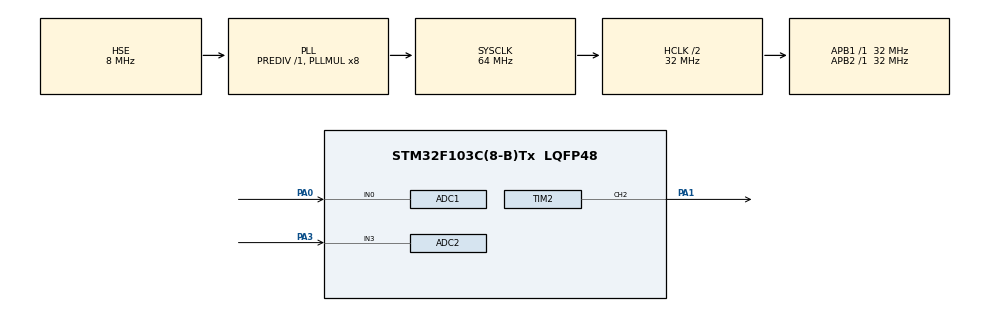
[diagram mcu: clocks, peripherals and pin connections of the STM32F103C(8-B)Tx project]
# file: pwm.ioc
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ADC1.Channel-0\#ChannelRegularConversion=ADC_CHANNEL_0
ADC1.ContinuousConvMode=DISABLE
ADC1.DataAlign=ADC_DATAALIGN_RIGHT
ADC1.DiscontinuousConvMode=DISABLE
ADC1.EnableAnalogWatchDog=false
ADC1.EnableRegularConversion=ENABLE
ADC1.ExternalTrigConvEdgeChoice=NONE
ADC1.InjNumberOfConversion=0
ADC1.NbrOfConversion=1
ADC1.NbrOfConversionFlag=1
ADC1.Rank-0\#ChannelRegularConversion=1
ADC1.SamplingTime-0\#ChannelRegularConversion=ADC_SAMPLETIME_55CYCLES_5
ADC1.ScanConvMode=ADC_SCAN_DISABLE
ADC1.master=1
ADC2.Channel-4\#ChannelRegularConversion=ADC_CHANNEL_3
ADC2.NbrOfConversionFlag=1
ADC2.Rank-4\#ChannelRegularConversion=1
ADC2.SamplingTime-4\#ChannelRegularConversion=ADC_SAMPLETIME_55CYCLES_5
Mcu.Family=STM32F1
Mcu.Name=STM32F103C(8-B)Tx
Mcu.Package=LQFP48
NVIC.ADC1_2_IRQn=true\:0\:0\:false\:false\:true
NVIC.PriorityGroup=NVIC_PRIORITYGROUP_4
PA0-WKUP.Signal=ADCx_IN0
PA1.Signal=S_TIM2_CH2
PA13.Mode=JTAG_5_pin
PA13.Signal=SYS_JTMS-SWDIO
PA14.Mode=JTAG_5_pin
PA14.Signal=SYS_JTCK-SWCLK
PA15.Mode=JTAG_5_pin
PA15.Signal=SYS_JTDI
PA3.Signal=ADCx_IN3
PB3.Mode=JTAG_5_pin
PB3.Signal=SYS_JTDO-TRACESWO
PB4.Mode=JTAG_5_pin
PB4.Signal=SYS_NJTRST
PD0-OSC_IN.Mode=HSE-External-Oscillator
PD0-OSC_IN.Signal=RCC_OSC_IN
PD1-OSC_OUT.Mode=HSE-External-Oscillator
PD1-OSC_OUT.Signal=RCC_OSC_OUT
ProjectManager.HeapSize=0x200
ProjectManager.StackSize=0x400
ProjectManager.TargetToolchain=MDK-ARM V5
RCC.ADCPresc=RCC_ADCPCLK2_DIV4
RCC.AHBCLKDivider=RCC_SYSCLK_DIV2
RCC.AHBFreq_Value=32000000
RCC.APB1Freq_Value=32000000
RCC.APB1TimFreq_Value=32000000
RCC.APB2Freq_Value=32000000
RCC.APB2TimFreq_Value=32000000
RCC.HCLKFreq_Value=32000000
RCC.HSIState=RCC_HSI_ON
RCC.PLLMUL=RCC_PLL_MUL8
RCC.PLLSourceVirtual=RCC_PLLSOURCE_HSE
RCC.SYSCLKFreq_VALUE=64000000
RCC.SYSCLKSource=RCC_SYSCLKSOURCE_PLLCLK
RCC.USBFreq_Value=64000000
SH.ADCx_IN0.0=ADC1_IN0,IN0
SH.ADCx_IN3.0=ADC2_IN3,IN3
SH.S_TIM2_CH2.0=TIM2_CH2,PWM Generation2 CH2
TIM2.Channel-PWM\ Generation2\ CH2=TIM_CHANNEL_2
TIM2.OCFastMode_PWM-PWM\ Generation2\ CH2=TIM_OCFAST_ENABLE
TIM2.Period=20
TIM2.Prescaler=32
TIM2.Pulse-PWM\ Generation2\ CH2=10
board=pwm

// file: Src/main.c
/**
  ******************************************************************************
  * File Name          : main.c
  * Description        : Main program body
  ******************************************************************************
  *
  * COPYRIGHT(c) 2017 STMicroelectronics
  *
  * Redistribution and use in source and binary forms, with or without modification,
  * are permitted provided that the following conditions are met:
  *   1. Redistributions of source code must retain the above copyright notice,
  *      this list of conditions and the following disclaimer.
  *   2. Redistributions in binary form must reproduce the above copyright notice,
  *      this list of conditions and the following disclaimer in the documentation
  *      and/or other materials provided with the distribution.
  *   3. Neither the name of STMicroelectronics nor the names of its contributors
  *      may be used to endorse or promote products derived from this software
  *      without specific prior written permission.
  *
  * THIS SOFTWARE IS PROVIDED BY THE COPYRIGHT HOLDERS AND CONTRIBUTORS "AS IS"
  * AND ANY EXPRESS OR IMPLIED WARRANTIES, INCLUDING, BUT NOT LIMITED TO, THE
  * IMPLIED WARRANTIES OF MERCHANTABILITY AND FITNESS FOR A PARTICULAR PURPOSE ARE
  * DISCLAIMED. IN NO EVENT SHALL THE COPYRIGHT HOLDER OR CONTRIBUTORS BE LIABLE
  * FOR ANY DIRECT, INDIRECT, INCIDENTAL, SPECIAL, EXEMPLARY, OR CONSEQUENTIAL
  * DAMAGES (INCLUDING, BUT NOT LIMITED TO, PROCUREMENT OF SUBSTITUTE GOODS OR
  * SERVICES; LOSS OF USE, DATA, OR PROFITS; OR BUSINESS INTERRUPTION) HOWEVER
  * CAUSED AND ON ANY THEORY OF LIABILITY, WHETHER IN CONTRACT, STRICT LIABILITY,
  * OR TORT (INCLUDING NEGLIGENCE OR OTHERWISE) ARISING IN ANY WAY OUT OF THE USE
  * OF THIS SOFTWARE, EVEN IF ADVISED OF THE POSSIBILITY OF SUCH DAMAGE.
  *
  ******************************************************************************
  */
#include "stm32f1xx_hal.h"

ADC_HandleTypeDef hadc1;
ADC_HandleTypeDef hadc2;

TIM_HandleTypeDef htim2;

/* USER CODE BEGIN PV */
/* Private variables ---------------------------------------------------------*/

volatile uint16_t freq = 0;
volatile uint16_t pwm = 0;
  	int32_t f = 0;
		int32_t p = 0;
/* USER CODE END PV */

void SystemClock_Config(void);
static void MX_GPIO_Init(void);
static void MX_ADC1_Init(void);
static void MX_TIM2_Init(void);
static void MX_ADC2_Init(void);

void HAL_TIM_MspPostInit(TIM_HandleTypeDef *htim);

/* USER CODE BEGIN PFP */
/* Private function prototypes -----------------------------------------------*/

/* USER CODE END PFP */

/* USER CODE BEGIN 0 */

void HAL_ADC_ConvCpltCallback(ADC_HandleTypeDef* hadc){
	if(hadc->Instance == ADC1)
		freq = HAL_ADC_GetValue(hadc);
	if(hadc->Instance == ADC2)
		pwm = HAL_ADC_GetValue(hadc);
}

/* USER CODE END 0 */

int main(void)
{

  /* MCU Configuration----------------------------------------------------------*/

  /* Reset of all peripherals, Initializes the Flash interface and the Systick. */
  HAL_Init();

  /* Configure the system clock */
  SystemClock_Config();

  /* Initialize all configured peripherals */
  MX_GPIO_Init();
  MX_ADC1_Init();
  MX_TIM2_Init();
  MX_ADC2_Init();

  /* USER CODE BEGIN 2 */
//	HAL_TIM_Base_Start(&htim2);
HAL_TIM_PWM_Start(&htim2, TIM_CHANNEL_2);
  /* USER CODE END 2 */

  /* Infinite loop */
  while (1)
  {
p++;
if(p==255)p = 1;
		__HAL_TIM_SetCompare(&htim2,TIM_CHANNEL_2,p);
		HAL_Delay(300);
  /* USER CODE BEGIN 3 */
//		HAL_ADC_Start_IT(&hadc1);
//		HAL_ADC_Start_IT(&hadc2);
//		HAL_Delay(100);
//		if(freq > 150) f =freq-150; else f = 0;

//		p = (f*(pwm))/(4096);
//		__HAL_TIM_SetCompare(&htim2,TIM_CHANNEL_2,p);
//		__HAL_TIM_SetAutoreload(&htim2,f);
// 	HAL_Delay(100);

  }
  /* USER CODE END 3 */

}

/** System Clock Configuration
*/
void SystemClock_Config(void)
{

  RCC_OscInitTypeDef RCC_OscInitStruct;
  RCC_ClkInitTypeDef RCC_ClkInitStruct;
  RCC_PeriphCLKInitTypeDef PeriphClkInit;

  RCC_OscInitStruct.OscillatorType = RCC_OSCILLATORTYPE_HSE;
  RCC_OscInitStruct.HSEState = RCC_HSE_ON;
  RCC_OscInitStruct.HSEPredivValue = RCC_HSE_PREDIV_DIV1;
  RCC_OscInitStruct.PLL.PLLState = RCC_PLL_ON;
  RCC_OscInitStruct.PLL.PLLSource = RCC_PLLSOURCE_HSE;
  RCC_OscInitStruct.PLL.PLLMUL = RCC_PLL_MUL8;
  HAL_RCC_OscConfig(&RCC_OscInitStruct);

  RCC_ClkInitStruct.ClockType = RCC_CLOCKTYPE_HCLK|RCC_CLOCKTYPE_SYSCLK
                              |RCC_CLOCKTYPE_PCLK1|RCC_CLOCKTYPE_PCLK2;
  RCC_ClkInitStruct.SYSCLKSource = RCC_SYSCLKSOURCE_PLLCLK;
  RCC_ClkInitStruct.AHBCLKDivider = RCC_SYSCLK_DIV2;
  RCC_ClkInitStruct.APB1CLKDivider = RCC_HCLK_DIV1;
  RCC_ClkInitStruct.APB2CLKDivider = RCC_HCLK_DIV1;
  HAL_RCC_ClockConfig(&RCC_ClkInitStruct, FLASH_LATENCY_1);

  PeriphClkInit.PeriphClockSelection = RCC_PERIPHCLK_ADC;
  PeriphClkInit.AdcClockSelection = RCC_ADCPCLK2_DIV4;
  HAL_RCCEx_PeriphCLKConfig(&PeriphClkInit);

  HAL_SYSTICK_Config(HAL_RCC_GetHCLKFreq()/1000);

  HAL_SYSTICK_CLKSourceConfig(SYSTICK_CLKSOURCE_HCLK);

  /* SysTick_IRQn interrupt configuration */
  HAL_NVIC_SetPriority(SysTick_IRQn, 0, 0);
}

/* ADC1 init function */
void MX_ADC1_Init(void)
{

  ADC_ChannelConfTypeDef sConfig;

    /**Common config
    */
  hadc1.Instance = ADC1;
  hadc1.Init.ScanConvMode = ADC_SCAN_DISABLE;
  hadc1.Init.ContinuousConvMode = DISABLE;
  hadc1.Init.DiscontinuousConvMode = DISABLE;
  hadc1.Init.ExternalTrigConv = ADC_SOFTWARE_START;
  hadc1.Init.DataAlign = ADC_DATAALIGN_RIGHT;
  hadc1.Init.NbrOfConversion = 1;
  HAL_ADC_Init(&hadc1);

    /**Configure Regular Channel
    */
  sConfig.Channel = ADC_CHANNEL_0;
  sConfig.Rank = 1;
  sConfig.SamplingTime = ADC_SAMPLETIME_55CYCLES_5;
  HAL_ADC_ConfigChannel(&hadc1, &sConfig);

}

/* ADC2 init function */
void MX_ADC2_Init(void)
{

  ADC_ChannelConfTypeDef sConfig;

    /**Common config
    */
  hadc2.Instance = ADC2;
  hadc2.Init.ScanConvMode = ADC_SCAN_DISABLE;
  hadc2.Init.ContinuousConvMode = DISABLE;
  hadc2.Init.DiscontinuousConvMode = DISABLE;
  hadc2.Init.ExternalTrigConv = ADC_SOFTWARE_START;
  hadc2.Init.DataAlign = ADC_DATAALIGN_RIGHT;
  hadc2.Init.NbrOfConversion = 1;
  HAL_ADC_Init(&hadc2);

    /**Configure Regular Channel
    */
  sConfig.Channel = ADC_CHANNEL_3;
  sConfig.Rank = 1;
  sConfig.SamplingTime = ADC_SAMPLETIME_55CYCLES_5;
  HAL_ADC_ConfigChannel(&hadc2, &sConfig);

}

/* TIM2 init function */
void MX_TIM2_Init(void)
{

  TIM_MasterConfigTypeDef sMasterConfig;
  TIM_OC_InitTypeDef sConfigOC;

  htim2.Instance = TIM2;
  htim2.Init.Prescaler = 1;
  htim2.Init.CounterMode = TIM_COUNTERMODE_UP;
  htim2.Init.Period = 255;
  htim2.Init.ClockDivision = TIM_CLOCKDIVISION_DIV1;
  HAL_TIM_PWM_Init(&htim2);

  sMasterConfig.MasterOutputTrigger = TIM_TRGO_RESET;
  sMasterConfig.MasterSlaveMode = TIM_MASTERSLAVEMODE_DISABLE;
  HAL_TIMEx_MasterConfigSynchronization(&htim2, &sMasterConfig);

  sConfigOC.OCMode = TIM_OCMODE_PWM1;
  sConfigOC.Pulse = 0;
  sConfigOC.OCPolarity = TIM_OCPOLARITY_HIGH;
  sConfigOC.OCFastMode = TIM_OCFAST_ENABLE;
  HAL_TIM_PWM_ConfigChannel(&htim2, &sConfigOC, TIM_CHANNEL_2);

  HAL_TIM_MspPostInit(&htim2);

}

/** Configure pins as
        * Analog
        * Input
        * Output
        * EVENT_OUT
        * EXTI
*/
void MX_GPIO_Init(void)
{

  /* GPIO Ports Clock Enable */
  __HAL_RCC_GPIOD_CLK_ENABLE();
  __HAL_RCC_GPIOA_CLK_ENABLE();
  __HAL_RCC_GPIOB_CLK_ENABLE();

}

/************************ (C) COPYRIGHT STMicroelectronics *****END OF FILE****/
